# allwinner_d1_unofficial register map
File version: 0.1
Registers are 32-bit, read-write, reset 0x0 unless marked. A register's access mark holds for its fields unless they carry their own. Offsets are from the block's base; [hi:lo] are bit positions; {n}, {i} and the like mark numbered series.

## SYS_CFG — System Configuration
Base 0x03000000
0x08 DSP_BOOT_RAMMAP — DSP Boot SRAM Remap Control Register
  [0] DSP_BOOT_SRAM_REMAP_ENABLE
    0=DSP_SYS; 1=SYS_BOOT
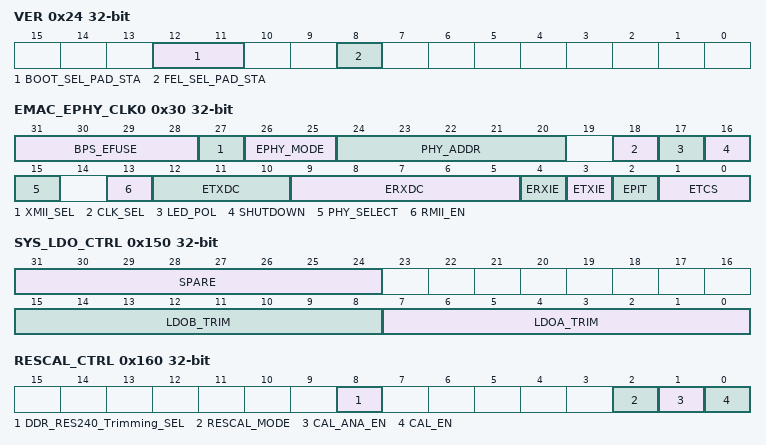
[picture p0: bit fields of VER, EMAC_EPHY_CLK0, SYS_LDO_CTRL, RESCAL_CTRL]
0x24 VER ro — Version Register
  [12:11] BOOT_SEL_PAD_STA
  [8] FEL_SEL_PAD_STA — Fel Select Pin Status
    0=RUN_FEL; 1=TRY_MEDIA_BOOT
0x30 EMAC_EPHY_CLK0 — EMAC-EPHY Clock Register 0
  [31:28] BPS_EFUSE
  [27] XMII_SEL
    0=Internal; 1=External
  [26:25] EPHY_MODE
    0=Normal; 1=Simulation; 2=AFE_Test
  [24:20] PHY_ADDR
  [18] CLK_SEL
    0=F25M; 1=F24M
  [17] LED_POL
    0=High; 1=Low
  [16] SHUTDOWN
    0=Power_up; 1=Shut_down
  [15] PHY_SELECT
    0=External; 1=Internal
  [13] RMII_EN
    0=Disable; 1=Enable
  [12:10] ETXDC
  [9:5] ERXDC
  [4] ERXIE
    0=Disable; 1=Enable
  [3] ETXIE
    0=Disable; 1=Enable
  [2] EPIT
    0=MII; 1=RGMII
  [1:0] ETCS
    0=MII; 1=External_GMII_RGMII; 2=Internal_GMII_RGMII
0x150 SYS_LDO_CTRL — System LDO Control Register
  [31:24] SPARE
  [15:8] LDOB_TRIM
    0=O1_167; 1=O1_18; 2=O1_193; 3=O1_207; 4=O1_22; 5=O1_233; 6=O1_247; 7=O1_260; 8=O1_273; 9=O1_287; 10=O1_3; 11=O1_313; 12=O1_327; 13=O1_340; 14=O1_353; 15=O1_367; 16=O1_38; 17=O1_393; 18=O1_407; 19=O1_42; 20=O1_433; 21=O1_447; 22=O1_46; 23=O1_473; 24=O1_487; 25=O1_5; 26=O1_513; 27=O1_527; 28=O1_54; 29=O1_553; 30=O1_567; 31=O1_58; 32=O1_593; 33=O1_607; 34=O1_627; 35=O1_64; 36=O1_653; 37=O1_667; 38=O1_680; 39=O1_693; 40=O1_707; 41=O1_720; 42=O1_733; 43=O1_747; 44=O1_76; 45=O1_773; 46=O1_787; 47=O1_8; 48=O1_813; 49=O1_827; 50=O1_84; 51=O1_853; 52=O1_867; 53=O1_88; 54=O1_893; 55=O1_907; 56=O1_92; 57=O1_933; 58=O1_947; 59=O1_96; 60=O1_973; 61=O1_987; 62=O2; 63=O2_013
  [7:0] LDOA_TRIM
    0=O1_593; 1=O1_607; 2=O1_627; 3=O1_64; 4=O1_653; 5=O1_667; 6=O1_680; 7=O1_693; 8=O1_707; 9=O1_720; 10=O1_733; 11=O1_747; 12=O1_76; 13=O1_773; 14=O1_787; 15=O1_8; 16=O1_813; 17=O1_827; 18=O1_84; 19=O1_853; 20=O1_867; 21=O1_88; 22=O1_893; 23=O1_907; 24=O1_92; 25=O1_933; 26=O1_947; 27=O1_96; 28=O1_973; 29=O1_987; 30=O2; 31=O2_013
0x160 RESCAL_CTRL — Resistor Calibration Control Register
  [8] DDR_RES240_Trimming_SEL — 240ohms Resistor Trimming Source Select
    0=RESCAL; 1=RES240_TRIM
  [2] RESCAL_MODE — RESCAL Calibration Mode Select
    0=Auto_Calibration
  [1] CAL_ANA_EN — Calibration Circuits Analog Enable
    0=Disable; 1=Enable
  [0] CAL_EN — Auto Calibration Enable
    0=Disable; 1=Enable
0x168 RES240_CTRL — 240ohms Resistor Manual Control Register
  [5:0] DDR_RES240_TRIM — 240ohms Resistor trimming bit
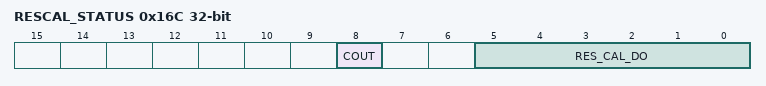
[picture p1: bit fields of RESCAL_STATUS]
0x16C RESCAL_STATUS ro — Resistor Calibration Status Register
  [8] COUT — Calibration Circuits Analog COmpare Output
  [5:0] RES_CAL_DO — RESCAL Calibration Results Output

## RISCV_CFG — RISC-V System Configuration
Base 0x06010000
0x04 RISCV_STA_ADD0_REG — RISCV Start Address0 Register
0x08 RISCV_STA_ADD1_REG — RISCV Start Address1 Register
  [7:0] STA_ADD_H — Start Address High 8-bit
0x10 RF1P_CFG_REG — RF1P Configuration Register
  [7:0] RF1P_CFG — RF1P Configuration
0x1C ROM_CFG_REG — ROM Configuration Register
  [7:0] ROM_CFG — ROM Configuration
0x20 WAKEUP_EN_REG — Wakeup Enable Register
  [0] WP_EN — Wakeup Enable
{0x24+4i} WAKEUP_MASK{i}_REG (i=0..4) — Wakeup Mask Register
0x40 TS_TMODE_SEL_REG — Timestamp Test Mode Select Register
  [0] TS_TEST_MODE_EN — Timestamp Test Mode Enable
    0=Normal; 1=Test
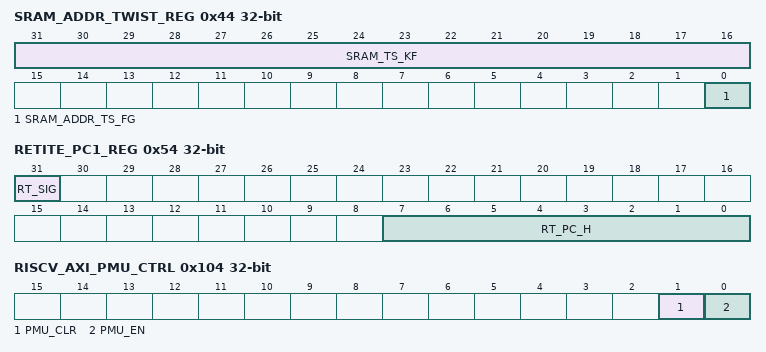
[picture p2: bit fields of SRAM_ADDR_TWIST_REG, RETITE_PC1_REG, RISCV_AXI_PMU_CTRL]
0x44 SRAM_ADDR_TWIST_REG — SRAM Address Twist Register
  [31:16] SRAM_TS_KF wo — SRAM Twist Keyfield
  [0] SRAM_ADDR_TS_FG — SRAM Address Twist Flag
0x48 WORK_MODE_REG ro — Work Mode Register
  [1:0] WM_STA — Work Mode Status
    0=Normal; 1=Low_Power; 2=Debug
0x50 RETITE_PC0_REG ro — Retire PC0 Register
0x54 RETITE_PC1_REG ro — Retire PC1 Register
  [31] RT_SIG — Retire Signal
    0=not_have; 1=have
  [7:0] RT_PC_H — Retire PC[39:32]
{0x60+4i} IRQ_MODE{i}_REG (i=0..4) — IRQ Mode Register
0x104 RISCV_AXI_PMU_CTRL — RISCV AXI PMU Control Register
  [1] PMU_CLR write-clears — PMU Clear
    0=no_operation; 1=cleared
  [0] PMU_EN — PMU Enable
    0=disabled; 1=enabled
0x108 RISCV_AXI_PMU_PRD — RISCV AXI PMU Period Register
0x10C RISCV_AXI_PMU_LAT_RD ro — RISCV AXI PMU Read Latency Register
0x110 RISCV_AXI_PMU_LAT_WR ro — RISCV AXI PMU Write Latency Register
0x114 RISCV_AXI_PMU_REQ_RD ro — RISCV AXI PMU Read Request Register
0x118 RISCV_AXI_PMU_REQ_WR ro — RISCV AXI PMU Write Request Register
0x11C RISCV_AXI_PMU_BW_RD ro — RISCV AXI PMU Read Bandwidth Register
0x120 RISCV_AXI_PMU_BW_WR ro — RISCV AXI PMU Write Bandwidth Register
